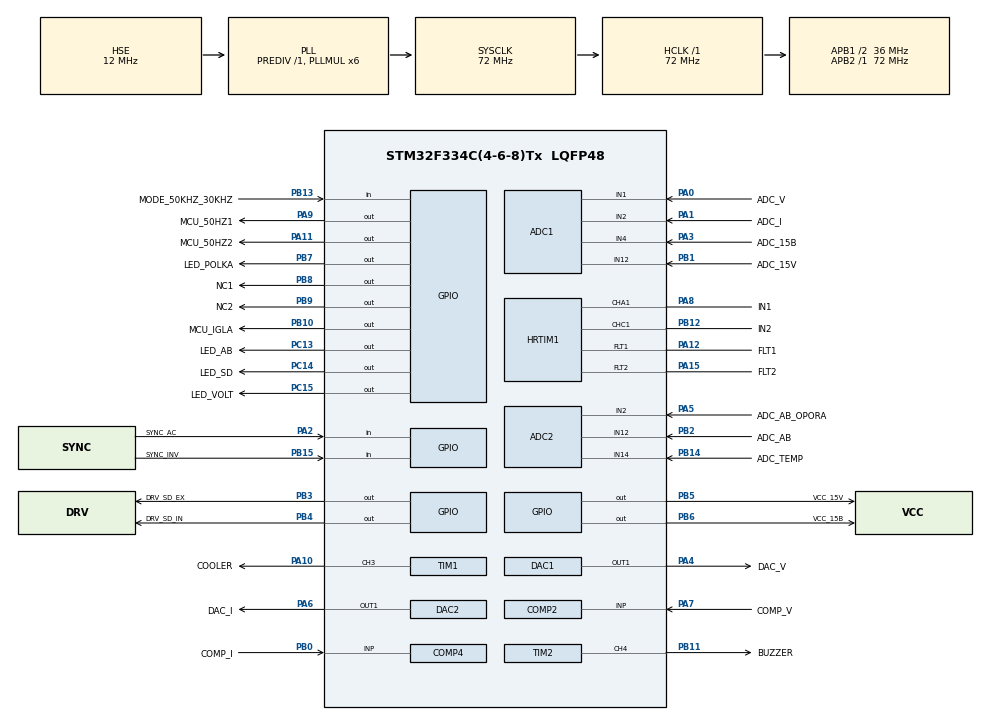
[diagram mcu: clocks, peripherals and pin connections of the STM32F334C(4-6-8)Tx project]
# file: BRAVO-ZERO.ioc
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ADC1.AWD1HighThreshold=2500
ADC1.AWD1ITMode=ENABLE
ADC1.AWD1LowThreshold=1500
ADC1.Channel-3\#ChannelRegularConversion=ADC_CHANNEL_4
ADC1.Channel-4\#ChannelRegularConversion=ADC_CHANNEL_12
ADC1.ContinuousConvMode=ENABLE
ADC1.DMAContinuousRequests=ENABLE
ADC1.EOCSelection=ADC_EOC_SEQ_CONV
ADC1.EnableAnalogWatchDog1=true
ADC1.EnableRegularConversion=ENABLE
ADC1.ExternalTrigInjecConv=ADC_EXTERNALTRIGINJECCONV_HRTIM_TRG2
ADC1.ExternalTrigInjecConvEdge=ADC_EXTERNALTRIGINJECCONV_EDGE_RISINGFALLING
ADC1.InjNumberOfConversion=2
ADC1.InjectedChannel-1\#ChannelInjectedConversion=ADC_CHANNEL_1
ADC1.InjectedChannel-2\#ChannelInjectedConversion=ADC_CHANNEL_2
ADC1.InjectedConvMode=None
ADC1.InjectedOffset-1\#ChannelInjectedConversion=0
ADC1.InjectedOffset-2\#ChannelInjectedConversion=0
ADC1.InjectedOffsetNumber-1\#ChannelInjectedConversion=ADC_OFFSET_NONE
ADC1.InjectedOffsetNumber-2\#ChannelInjectedConversion=ADC_OFFSET_NONE
ADC1.InjectedRank-1\#ChannelInjectedConversion=1
ADC1.InjectedRank-2\#ChannelInjectedConversion=2
ADC1.InjectedSamplingTime-1\#ChannelInjectedConversion=ADC_SAMPLETIME_19CYCLES_5
ADC1.InjectedSamplingTime-2\#ChannelInjectedConversion=ADC_SAMPLETIME_19CYCLES_5
ADC1.NbrOfConversion=2
ADC1.NbrOfConversionFlag=1
ADC1.Offset-3\#ChannelRegularConversion=0
ADC1.Offset-4\#ChannelRegularConversion=0
ADC1.OffsetNumber-3\#ChannelRegularConversion=ADC_OFFSET_NONE
ADC1.OffsetNumber-4\#ChannelRegularConversion=ADC_OFFSET_NONE
ADC1.QueueInjectedContext=ENABLE
ADC1.Rank-3\#ChannelRegularConversion=1
ADC1.Rank-4\#ChannelRegularConversion=2
ADC1.SamplingTime-3\#ChannelRegularConversion=ADC_SAMPLETIME_601CYCLES_5
ADC1.SamplingTime-4\#ChannelRegularConversion=ADC_SAMPLETIME_601CYCLES_5
ADC1.WatchdogMode=ADC_ANALOGWATCHDOG_ALL_REG
ADC1.master=1
ADC2.AWD1HighThreshold=2500
ADC2.AWD1ITMode=ENABLE
ADC2.AWD1LowThreshold=1500
ADC2.Channel-0\#ChannelRegularConversion=ADC_CHANNEL_14
ADC2.Channel-1\#ChannelRegularConversion=ADC_CHANNEL_12
ADC2.Channel-2\#ChannelRegularConversion=ADC_CHANNEL_2
ADC2.ContinuousConvMode=ENABLE
ADC2.DMAContinuousRequests=ENABLE
ADC2.EOCSelection=ADC_EOC_SEQ_CONV
ADC2.EnableAnalogWatchDog1=true
ADC2.EnableInjectedConversion=DISABLE
ADC2.NbrOfConversion=3
ADC2.NbrOfConversionFlag=1
ADC2.Offset-0\#ChannelRegularConversion=0
ADC2.Offset-1\#ChannelRegularConversion=0
ADC2.Offset-2\#ChannelRegularConversion=0
ADC2.OffsetNumber-0\#ChannelRegularConversion=ADC_OFFSET_NONE
ADC2.OffsetNumber-1\#ChannelRegularConversion=ADC_OFFSET_NONE
ADC2.OffsetNumber-2\#ChannelRegularConversion=ADC_OFFSET_NONE
ADC2.Rank-0\#ChannelRegularConversion=1
ADC2.Rank-1\#ChannelRegularConversion=2
ADC2.Rank-2\#ChannelRegularConversion=3
ADC2.SamplingTime-0\#ChannelRegularConversion=ADC_SAMPLETIME_601CYCLES_5
ADC2.SamplingTime-1\#ChannelRegularConversion=ADC_SAMPLETIME_601CYCLES_5
ADC2.SamplingTime-2\#ChannelRegularConversion=ADC_SAMPLETIME_601CYCLES_5
ADC2.WatchdogChannel=ADC_CHANNEL_12
COMP2.InvertingInput=COMP_INVERTINGINPUT_DAC1_CH1
COMP2.TriggerMode=COMP_TRIGGERMODE_IT_RISING_FALLING
COMP4.InvertingInput=COMP_INVERTINGINPUT_DAC2_CH1
COMP4.TriggerMode=COMP_TRIGGERMODE_IT_RISING_FALLING
Dma.ADC1.2.Direction=DMA_PERIPH_TO_MEMORY
Dma.ADC1.2.Instance=DMA1_Channel1
Dma.ADC1.2.MemDataAlignment=DMA_MDATAALIGN_HALFWORD
Dma.ADC1.2.MemInc=DMA_MINC_ENABLE
Dma.ADC1.2.Mode=DMA_CIRCULAR
Dma.ADC1.2.PeriphDataAlignment=DMA_PDATAALIGN_HALFWORD
Dma.ADC1.2.PeriphInc=DMA_PINC_DISABLE
Dma.ADC1.2.Priority=DMA_PRIORITY_HIGH
Dma.ADC2.3.Direction=DMA_PERIPH_TO_MEMORY
Dma.ADC2.3.Instance=DMA1_Channel4
Dma.ADC2.3.MemDataAlignment=DMA_MDATAALIGN_HALFWORD
Dma.ADC2.3.MemInc=DMA_MINC_ENABLE
Dma.ADC2.3.Mode=DMA_CIRCULAR
Dma.ADC2.3.PeriphDataAlignment=DMA_PDATAALIGN_HALFWORD
Dma.ADC2.3.PeriphInc=DMA_PINC_DISABLE
Dma.ADC2.3.Priority=DMA_PRIORITY_MEDIUM
Dma.Request0=TIM17_CH1/UP
Dma.Request1=TIM16_CH1/UP
Dma.Request2=ADC1
Dma.Request3=ADC2
Dma.TIM16_CH1/UP.1.Direction=DMA_PERIPH_TO_MEMORY
Dma.TIM16_CH1/UP.1.Instance=DMA1_Channel6
Dma.TIM16_CH1/UP.1.MemDataAlignment=DMA_MDATAALIGN_HALFWORD
Dma.TIM16_CH1/UP.1.MemInc=DMA_MINC_ENABLE
Dma.TIM16_CH1/UP.1.Mode=DMA_CIRCULAR
Dma.TIM16_CH1/UP.1.PeriphDataAlignment=DMA_PDATAALIGN_HALFWORD
Dma.TIM16_CH1/UP.1.PeriphInc=DMA_PINC_DISABLE
Dma.TIM16_CH1/UP.1.Priority=DMA_PRIORITY_LOW
Dma.TIM17_CH1/UP.0.Direction=DMA_PERIPH_TO_MEMORY
Dma.TIM17_CH1/UP.0.Instance=DMA1_Channel7
Dma.TIM17_CH1/UP.0.MemDataAlignment=DMA_MDATAALIGN_HALFWORD
Dma.TIM17_CH1/UP.0.MemInc=DMA_MINC_ENABLE
Dma.TIM17_CH1/UP.0.Mode=DMA_CIRCULAR
Dma.TIM17_CH1/UP.0.PeriphDataAlignment=DMA_PDATAALIGN_HALFWORD
Dma.TIM17_CH1/UP.0.PeriphInc=DMA_PINC_DISABLE
Dma.TIM17_CH1/UP.0.Priority=DMA_PRIORITY_LOW
HRTIM1.ADCTrigger_Id1=__NULL
HRTIM1.ADCTrigger_Id2=__NULL
HRTIM1.CaptureUnit1-No_output_TB=HRTIM_CAPTUREUNIT_1
HRTIM1.CaptureUnit1-No_output_TD=HRTIM_CAPTUREUNIT_1
HRTIM1.CaptureUnit1-Output_TA1=__NULL
HRTIM1.CaptureUnit1-Output_TC1=__NULL
HRTIM1.CaptureUnit2-No_output_TB=HRTIM_CAPTUREUNIT_2
HRTIM1.CaptureUnit2-No_output_TD=HRTIM_CAPTUREUNIT_2
HRTIM1.CaptureUnit2-Output_TA1=__NULL
HRTIM1.CaptureUnit2-Output_TC1=__NULL
HRTIM1.CompareUnit1-MasterTimer=HRTIM_COMPAREUNIT_1
HRTIM1.CompareUnit1-No_output_TB=__NULL
HRTIM1.CompareUnit1-Output_TA1=HRTIM_COMPAREUNIT_1
HRTIM1.CompareUnit1-Output_TC1=HRTIM_COMPAREUNIT_1
HRTIM1.CompareUnit2-MasterTimer=HRTIM_COMPAREUNIT_2
HRTIM1.CompareUnit2-Output_TA1=__NULL
HRTIM1.CompareUnit2-Output_TC1=__NULL
HRTIM1.CompareUnit3-MasterTimer=HRTIM_COMPAREUNIT_3
HRTIM1.CompareUnit3-Output_TA1=__NULL
HRTIM1.CompareUnit4-MasterTimer=HRTIM_COMPAREUNIT_4
HRTIM1.CompareUnit4-Output_TA1=__NULL
HRTIM1.CompareValue1-MasterTimer=1700
HRTIM1.CompareValue1-No_output_TB=25000
HRTIM1.CompareValue1-Output_TA1=23300
HRTIM1.CompareValue1-Output_TC1=48300
HRTIM1.CompareValue2-MasterTimer=23300
HRTIM1.CompareValue3-MasterTimer=26700
HRTIM1.CompareValue4-MasterTimer=48300
HRTIM1.Event1-Output_TA1=__NULL
HRTIM1.Event_EEV1=HRTIM_EVENT_1
HRTIM1.Event_EEV2=HRTIM_EVENT_2
HRTIM1.Event_EEV3=__NULL
HRTIM1.Event_EEV4=__NULL
HRTIM1.Event_EEV5=__NULL
HRTIM1.Event_EEV6=__NULL
HRTIM1.Event_EEV7=__NULL
HRTIM1.FastMode_EEV1=HRTIM_EVENTFASTMODE_ENABLE
HRTIM1.FastMode_EEV2=HRTIM_EVENTFASTMODE_ENABLE
HRTIM1.FaultEnable_Source1-No_output_TB=HRTIM_TIMFAULTENABLE_FAULT1
HRTIM1.FaultEnable_Source1-No_output_TD=HRTIM_TIMFAULTENABLE_FAULT1
HRTIM1.FaultEnable_Source1-Output_TA1=HRTIM_TIMFAULTENABLE_FAULT1
HRTIM1.FaultEnable_Source1-Output_TC1=HRTIM_TIMFAULTENABLE_FAULT1
HRTIM1.FaultEnable_Source2-No_output_TB=HRTIM_TIMFAULTENABLE_FAULT2
HRTIM1.FaultEnable_Source2-No_output_TD=HRTIM_TIMFAULTENABLE_FAULT2
HRTIM1.FaultEnable_Source2-Output_TA1=HRTIM_TIMFAULTENABLE_FAULT2
HRTIM1.FaultEnable_Source2-Output_TC1=HRTIM_TIMFAULTENABLE_FAULT2
HRTIM1.FaultLevel1-Output_TA1=HRTIM_OUTPUTFAULTLEVEL_INACTIVE
HRTIM1.FaultLevel1-Output_TC1=HRTIM_OUTPUTFAULTLEVEL_INACTIVE
HRTIM1.Filter_FaultLine1=HRTIM_FAULTFILTER_15
HRTIM1.Filter_FaultLine2=HRTIM_FAULTFILTER_15
HRTIM1.HRTIMInterruptResquests1=HRTIM_IT_FLT1
HRTIM1.HRTIMInterruptResquests2=HRTIM_IT_FLT2
HRTIM1.HRTIMInterruptResquests3=HRTIM_IT_SYSFLT
HRTIM1.InterruptRequests1-No_output_TB=HRTIM_TIM_IT_CPT1
HRTIM1.InterruptRequests1-No_output_TD=HRTIM_TIM_IT_CPT1
HRTIM1.InterruptRequests1_Master=HRTIM_MASTER_IT_MREP
HRTIM1.InterruptRequests2-No_output_TB=HRTIM_TIM_IT_CPT2
HRTIM1.InterruptRequests2-No_output_TD=HRTIM_TIM_IT_CPT2
HRTIM1.InterruptRequests2_Master=HRTIM_MASTER_IT_MCMP1
HRTIM1.InterruptRequests3_Master=HRTIM_MASTER_IT_MCMP2
HRTIM1.InterruptRequests4_Master=HRTIM_MASTER_IT_MCMP3
HRTIM1.InterruptRequests5_Master=HRTIM_MASTER_IT_MCMP4
HRTIM1.ModeTimeBase-No_output_TB=HRTIM_MODE_SINGLESHOT_RETRIGGERABLE
HRTIM1.ModeTimeBase-No_output_TD=HRTIM_MODE_SINGLESHOT_RETRIGGERABLE
HRTIM1.ModeTimeBase-Output_TA1=HRTIM_MODE_SINGLESHOT_RETRIGGERABLE
HRTIM1.ModeTimeBase-Output_TC1=HRTIM_MODE_SINGLESHOT_RETRIGGERABLE
HRTIM1.NumberDMARequests_Master=0
HRTIM1.NumberDMARequests_TA=0
HRTIM1.NumberDMARequests_TC=0
HRTIM1.NumberFaultEnable-No_output_TB=2
HRTIM1.NumberFaultEnable-No_output_TD=2
HRTIM1.NumberFaultEnable-Output_TA1=2
HRTIM1.NumberFaultEnable-Output_TC1=2
HRTIM1.NumberInterruptRequests-No_output_TB=2
HRTIM1.NumberInterruptRequests-No_output_TD=2
HRTIM1.NumberInterruptRequests-Output_TA1=0
HRTIM1.NumberInterruptRequests-Output_TC1=0
HRTIM1.NumberInterruptRequests_Master-MasterTimer=5
HRTIM1.NumberResetSource1-Output_TA1=7
HRTIM1.NumberResetSource1-Output_TC1=7
HRTIM1.NumberResetTrigger-No_output_TB=1
HRTIM1.NumberResetTrigger-No_output_TD=1
HRTIM1.NumberResetTrigger-Output_TA1=1
HRTIM1.NumberResetTrigger-Output_TC1=1
HRTIM1.NumberSetSource1-Output_TA1=1
HRTIM1.NumberSetSource1-Output_TC1=1
HRTIM1.NumberTriggerSource_Captureconfig1-No_output_TB=1
HRTIM1.NumberTriggerSource_Captureconfig1-No_output_TD=1
HRTIM1.NumberTriggerSource_Captureconfig2-No_output_TB=1
HRTIM1.NumberTriggerSource_Captureconfig2-No_output_TD=1
HRTIM1.NumberUpdateTrigger-No_output_TB=1
HRTIM1.NumberUpdateTrigger-No_output_TD=1
HRTIM1.NumberUpdateTrigger-Output_TA1=1
HRTIM1.NumberUpdateTrigger-Output_TC1=1
HRTIM1.Periode_MASTER=50000
HRTIM1.Periode_TA=50000
HRTIM1.Periode_TB=50000
HRTIM1.Periode_TC=50000
HRTIM1.Periode_TD=50000
HRTIM1.PreloadEnable-MasterTimer=HRTIM_PRELOAD_ENABLED
HRTIM1.PreloadEnable-No_output_TB=HRTIM_PRELOAD_ENABLED
HRTIM1.PreloadEnable-No_output_TD=HRTIM_PRELOAD_ENABLED
HRTIM1.PreloadEnable-Output_TA1=HRTIM_PRELOAD_ENABLED
HRTIM1.PreloadEnable-Output_TC1=HRTIM_PRELOAD_ENABLED
HRTIM1.PrescalerRatio_MASTER=HRTIM_PRESCALERRATIO_MUL16
HRTIM1.PrescalerRatio_TA=HRTIM_PRESCALERRATIO_MUL16
HRTIM1.PrescalerRatio_TB=HRTIM_PRESCALERRATIO_MUL16
HRTIM1.PrescalerRatio_TC=HRTIM_PRESCALERRATIO_MUL16
HRTIM1.PrescalerRatio_TD=HRTIM_PRESCALERRATIO_MUL16
HRTIM1.RepetitionUpdate-MasterTimer=HRTIM_UPDATEONREPETITION_ENABLED
HRTIM1.RepetitionUpdate-No_output_TB=HRTIM_UPDATEONREPETITION_DISABLED
HRTIM1.RepetitionUpdate-Output_TA1=HRTIM_UPDATEONREPETITION_DISABLED
HRTIM1.ResetOutput1_Source1-Output_TA1=HRTIM_OUTPUTRESET_EEV_1
HRTIM1.ResetOutput1_Source1-Output_TC1=HRTIM_OUTPUTRESET_EEV_1
HRTIM1.ResetOutput1_Source2-Output_TA1=HRTIM_OUTPUTRESET_EEV_2
HRTIM1.ResetOutput1_Source2-Output_TC1=HRTIM_OUTPUTRESET_EEV_2
HRTIM1.ResetOutput1_Source3-Output_TA1=HRTIM_OUTPUTRESET_MASTERCMP2
HRTIM1.ResetOutput1_Source3-Output_TC1=HRTIM_OUTPUTRESET_MASTERCMP4
HRTIM1.ResetOutput1_Source4-Output_TA1=HRTIM_OUTPUTRESET_MASTERCMP3
HRTIM1.ResetOutput1_Source4-Output_TC1=HRTIM_OUTPUTRESET_MASTERCMP1
HRTIM1.ResetOutput1_Source5-Output_TA1=HRTIM_OUTPUTRESET_MASTERCMP4
HRTIM1.ResetOutput1_Source5-Output_TC1=HRTIM_OUTPUTRESET_MASTERCMP2
HRTIM1.ResetOutput1_Source6-Output_TA1=HRTIM_OUTPUTRESET_MASTERPER
HRTIM1.ResetOutput1_Source6-Output_TC1=HRTIM_OUTPUTRESET_MASTERPER
HRTIM1.ResetOutput1_Source7-Output_TA1=HRTIM_OUTPUTRESET_TIMCMP1
HRTIM1.ResetOutput1_Source7-Output_TC1=HRTIM_OUTPUTRESET_TIMCMP1
HRTIM1.ResetTrigger1-No_output_TB=HRTIM_TIMRESETTRIGGER_UPDATE
HRTIM1.ResetTrigger1-No_output_TD=HRTIM_TIMRESETTRIGGER_UPDATE
HRTIM1.ResetTrigger1-Output_TA1=HRTIM_TIMRESETTRIGGER_MASTER_PER
HRTIM1.ResetTrigger1-Output_TC1=HRTIM_TIMRESETTRIGGER_MASTER_PER
HRTIM1.SetOutput1_Source1-Output_TA1=HRTIM_OUTPUTSET_MASTERCMP1
HRTIM1.SetOutput1_Source1-Output_TC1=HRTIM_OUTPUTSET_MASTERCMP3
HRTIM1.Source_EEV1=HRTIM_EVENTSRC_2
HRTIM1.TriggerCapture1_Source1-No_output_TB=HRTIM_CAPTURETRIGGER_TA1_RESET
HRTIM1.TriggerCapture1_Source1-No_output_TD=HRTIM_CAPTURETRIGGER_EEV_1
HRTIM1.TriggerCapture2_Source1-No_output_TB=HRTIM_CAPTURETRIGGER_TC1_RESET
HRTIM1.TriggerCapture2_Source1-No_output_TD=HRTIM_CAPTURETRIGGER_EEV_2
HRTIM1.UpdateTrigger1-No_output_TB=HRTIM_TIMUPDATETRIGGER_MASTER
HRTIM1.UpdateTrigger1-No_output_TD=HRTIM_TIMUPDATETRIGGER_MASTER
HRTIM1.UpdateTrigger1-Output_TA1=HRTIM_TIMUPDATETRIGGER_MASTER
HRTIM1.UpdateTrigger1-Output_TC1=HRTIM_TIMUPDATETRIGGER_MASTER
IWDG.Prescaler=IWDG_PRESCALER_256
Mcu.Family=STM32F3
Mcu.Name=STM32F334C(4-6-8)Tx
Mcu.Package=LQFP48
NVIC.COMP2_IRQn=true\:0\:0\:false\:false\:true\:false\:true
NVIC.COMP4_6_IRQn=true\:0\:0\:false\:false\:true\:false\:true
NVIC.DMA1_Channel1_IRQn=true\:0\:0\:false\:false\:true\:false\:true
NVIC.DMA1_Channel4_IRQn=true\:0\:0\:false\:false\:true\:false\:true
NVIC.DMA1_Channel6_IRQn=true\:0\:0\:false\:false\:true\:false\:true
NVIC.DMA1_Channel7_IRQn=true\:0\:0\:false\:false\:true\:false\:true
NVIC.HRTIM1_FLT_IRQn=true\:0\:0\:false\:false\:true\:true\:true
NVIC.HRTIM1_Master_IRQn=true\:0\:0\:false\:false\:true\:true\:true
NVIC.HRTIM1_TIMA_IRQn=true\:0\:0\:false\:false\:true\:true\:true
NVIC.HRTIM1_TIMB_IRQn=true\:0\:0\:false\:false\:true\:true\:true
NVIC.HRTIM1_TIMC_IRQn=true\:0\:0\:false\:false\:true\:true\:true
NVIC.HRTIM1_TIMD_IRQn=true\:0\:0\:false\:false\:true\:true\:true
NVIC.PVD_IRQn=true\:0\:0\:false\:false\:true\:true\:true
NVIC.PriorityGroup=NVIC_PRIORITYGROUP_4
PA0.GPIO_Label=ADC_V
PA0.Mode=IN1-Single-Ended
PA0.Signal=ADC1_IN1
PA1.GPIO_Label=ADC_I
PA1.Mode=IN2-Single-Ended
PA1.Signal=ADC1_IN2
PA10.GPIO_Label=COOLER
PA10.GPIO_Speed=GPIO_SPEED_FREQ_HIGH
PA10.Signal=S_TIM1_CH3
PA11.GPIO_Label=MCU_50HZ2
PA11.GPIO_Speed=GPIO_SPEED_FREQ_HIGH
PA11.Signal=GPIO_Output
PA12.GPIO_Label=FLT1
PA12.GPIO_Speed=GPIO_SPEED_FREQ_HIGH
PA12.Mode=Fault_Enable1
PA12.Signal=HRTIM1_FLT1
PA13.Mode=Serial_Wire
PA13.Signal=SYS_JTMS-SWDIO
PA14.Mode=Serial_Wire
PA14.Signal=SYS_JTCK-SWCLK
PA15.GPIO_Label=FLT2
PA15.GPIO_Speed=GPIO_SPEED_FREQ_HIGH
PA15.Mode=Fault_Enable2
PA15.Signal=HRTIM1_FLT2
PA2.GPIO_Label=SYNC_AC
PA2.Signal=GPIO_Input
PA3.GPIO_Label=ADC_15B
PA3.Mode=IN4-Single-Ended
PA3.Signal=ADC1_IN4
PA4.GPIO_Label=DAC_V
PA4.Signal=COMP_DAC11_group
PA5.GPIO_Label=ADC_AB_OPORA
PA5.Mode=IN2-Single-Ended
PA5.Signal=ADC2_IN2
PA6.GPIO_Label=DAC_I
PA6.Signal=COMP_DAC21_group
PA7.GPIO_Label=COMP_V
PA7.Mode=INP
PA7.Signal=COMP2_INP
PA8.GPIO_Label=IN1
PA8.Mode=Output_TA1
PA8.Signal=HRTIM1_CHA1
PA9.GPIO_Label=MCU_50HZ1
PA9.GPIO_Speed=GPIO_SPEED_FREQ_HIGH
PA9.Signal=GPIO_Output
PB0.GPIO_Label=COMP_I
PB0.Mode=INP
PB0.Signal=COMP4_INP
PB1.GPIO_Label=ADC_15V
PB1.Mode=IN12-Single-Ended
PB1.Signal=ADC1_IN12
PB10.GPIO_Label=MCU_IGLA
PB10.GPIO_Speed=GPIO_SPEED_FREQ_HIGH
PB10.Signal=GPIO_Output
PB11.GPIO_Label=BUZZER
PB11.GPIO_Speed=GPIO_SPEED_FREQ_HIGH
PB11.Signal=S_TIM2_CH4
PB12.GPIO_Label=IN2
PB12.Mode=Output_TC1
PB12.Signal=HRTIM1_CHC1
PB13.GPIO_Label=MODE_50KHZ_30KHZ
PB13.Signal=GPIO_Input
PB14.GPIO_Label=ADC_TEMP
PB14.Mode=IN14-Single-Ended
PB14.Signal=ADC2_IN14
PB15.GPIO_Label=SYNC_INV
PB15.Signal=GPIO_Input
PB2.GPIO_Label=ADC_AB
PB2.Mode=IN12-Single-Ended
PB2.Signal=ADC2_IN12
PB3.GPIO_Label=DRV_SD_EX
PB3.GPIO_Speed=GPIO_SPEED_FREQ_HIGH
PB3.Signal=GPIO_Output
PB4.GPIO_Label=DRV_SD_IN
PB4.GPIO_Speed=GPIO_SPEED_FREQ_HIGH
PB4.PinState=GPIO_PIN_SET
PB4.Signal=GPIO_Output
PB5.GPIO_Label=VCC_15V
PB5.GPIO_Speed=GPIO_SPEED_FREQ_HIGH
PB5.Signal=GPIO_Output
PB6.GPIO_FM6=SYSCFG_CFGR1_I2C_PB6_FMP
PB6.GPIO_Label=VCC_15B
PB6.GPIO_Speed=GPIO_SPEED_FREQ_HIGH
PB6.Signal=GPIO_Output
PB7.GPIO_FM7=SYSCFG_CFGR1_I2C_PB7_FMP
PB7.GPIO_Label=LED_POLKA
PB7.GPIO_Speed=GPIO_SPEED_FREQ_HIGH
PB7.PinState=GPIO_PIN_SET
PB7.Signal=GPIO_Output
PB8.GPIO_Label=NC1
PB8.Signal=GPIO_Output
PB9.GPIO_Label=NC2
PB9.Signal=GPIO_Output
PC13.GPIO_Label=LED_AB
PC13.GPIO_Speed=GPIO_SPEED_FREQ_LOW
PC13.PinState=GPIO_PIN_SET
PC13.Signal=GPIO_Output
PC14\ /\ OSC32_IN.GPIO_Label=LED_SD
PC14\ /\ OSC32_IN.GPIO_Speed=GPIO_SPEED_FREQ_HIGH
PC14\ /\ OSC32_IN.PinState=GPIO_PIN_SET
PC14\ /\ OSC32_IN.Signal=GPIO_Output
PC15\ /\ OSC32_OUT.GPIO_Label=LED_VOLT
PC15\ /\ OSC32_OUT.GPIO_Speed=GPIO_SPEED_FREQ_HIGH
PC15\ /\ OSC32_OUT.PinState=GPIO_PIN_SET
PC15\ /\ OSC32_OUT.Signal=GPIO_Output
PF0\ /\ OSC_IN.Mode=HSE-External-Oscillator
PF0\ /\ OSC_IN.Signal=RCC_OSC_IN
PF1\ /\ OSC_OUT.Mode=HSE-External-Oscillator
PF1\ /\ OSC_OUT.Signal=RCC_OSC_OUT
ProjectManager.HeapSize=0x200
ProjectManager.StackSize=0x400
ProjectManager.TargetToolchain=STM32CubeIDE
RCC.AHBFreq_Value=72000000
RCC.APB1CLKDivider=RCC_HCLK_DIV2
RCC.APB1Freq_Value=36000000
RCC.APB1TimFreq_Value=72000000
RCC.APB2Freq_Value=72000000
RCC.APB2TimFreq_Value=72000000
RCC.CortexFreq_Value=72000000
RCC.HCLKFreq_Value=72000000
RCC.HRTIMSelection=RCC_HRTIM1CLK_PLLCLK
RCC.HSE_VALUE=12000000
RCC.HSI_VALUE=8000000
RCC.LSE_VALUE=32768
RCC.PLLMUL=RCC_PLL_MUL6
RCC.PLLSourceVirtual=RCC_PLLSOURCE_HSE
RCC.SYSCLKFreq_VALUE=72000000
RCC.SYSCLKSourceVirtual=RCC_SYSCLKSOURCE_PLLCLK
SH.COMP_DAC11_group.0=DAC1_OUT1,DAC_OUT1
SH.COMP_DAC21_group.0=DAC2_OUT1,Switch_Enable_OUT1
SH.S_TIM1_CH3.0=TIM1_CH3,PWM Generation3 CH3
SH.S_TIM2_CH4.0=TIM2_CH4,PWM Generation4 CH4
TIM1.AutoReloadPreload=TIM_AUTORELOAD_PRELOAD_ENABLE
TIM1.Channel-PWM\ Generation3\ CH3=TIM_CHANNEL_3
TIM1.Period=35999
TIM1.Prescaler=1
TIM16.AutoReloadPreload=TIM_AUTORELOAD_PRELOAD_ENABLE
TIM16.ClockDivision=TIM_CLOCKDIVISION_DIV4
TIM16.Period=63999
TIM16.Prescaler=33749
TIM16.RepetitionCounter=0
TIM17.AutoReloadPreload=TIM_AUTORELOAD_PRELOAD_ENABLE
TIM17.ClockDivision=TIM_CLOCKDIVISION_DIV4
TIM17.Period=63999
TIM17.Prescaler=1124
TIM2.AutoReloadPreload=TIM_AUTORELOAD_PRELOAD_ENABLE
TIM2.Channel-PWM\ Generation4\ CH4=TIM_CHANNEL_4
TIM2.ClockDivision=TIM_CLOCKDIVISION_DIV1
TIM2.Period=63999
TIM2.Prescaler=5624
VP_COMP2_VS_DAC1OUT1.Mode=INM_DAC1OUT1
VP_COMP4_VS_DAC2OUT1.Mode=INM_DAC2OUT1
VP_HRTIM1_VS_hrtimMasterTimerNoOutput.Mode=MasterTimer
VP_HRTIM1_VS_hrtimTimerBNoOutput.Mode=No_output_TB
VP_HRTIM1_VS_hrtimTimerDNoOutput.Mode=No_output_TD
VP_IWDG_VS_IWDG.Mode=IWDG_Activate
VP_TIM16_VS_ClockSourceINT.Mode=Enable_Timer
VP_TIM17_VS_ClockSourceINT.Mode=Enable_Timer
VP_TIM1_VS_ClockSourceINT.Mode=Internal
VP_TIM2_VS_ClockSourceINT.Mode=Internal
board=custom

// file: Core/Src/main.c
/* USER CODE BEGIN Header */
/**
  ******************************************************************************
  * @file           : main.c
  * @brief          : Main program body
  ******************************************************************************
  * @attention
  *
  * <h2><center>&copy; Copyright (c) 2020 STMicroelectronics.
  * All rights reserved.</center></h2>
  *
  * This software component is licensed by ST under BSD 3-Clause license,
  * the "License"; You may not use this file except in compliance with the
  * License. You may obtain a copy of the License at:
  *                        opensource.org/licenses/BSD-3-Clause
  *
  ******************************************************************************
  */
/* USER CODE END Header */

#include "main.h"
#include "adc.h"
#include "comp.h"
#include "dac.h"
#include "dma.h"
#include "hrtim.h"
#include "iwdg.h"
#include "tim.h"
#include "gpio.h"

/* USER CODE BEGIN Includes */
#include "BRAVO_hal.h"
/* USER CODE END Includes */

void SystemClock_Config(void);

int main(void)
{
  /* USER CODE BEGIN 1 */
	Enable_SH_DEBUG();
  /* USER CODE END 1 */

  /* MCU Configuration--------------------------------------------------------*/

  /* Reset of all peripherals, Initializes the Flash interface and the Systick. */
  HAL_Init();

  /* Configure the system clock */
  SystemClock_Config();

  /* Initialize all configured peripherals */
  MX_GPIO_Init();
  MX_DMA_Init();
  MX_IWDG_Init();
  MX_ADC1_Init();
  MX_COMP2_Init();
  MX_COMP4_Init();
  MX_DAC1_Init();
  MX_DAC2_Init();
  MX_TIM1_Init();
  MX_TIM2_Init();
  MX_TIM16_Init();
  MX_TIM17_Init();
  MX_ADC2_Init();
  MX_HRTIM1_Init();
  /* USER CODE BEGIN 2 */

  BRAVO_Stop(); // STOP HRTIM
  VCC15V_ON(); // ON 15V POWER SUPPY
  COMP_DAC_Start(); // Start all DACs and COMPs

  BRAVO_SoftStart_ON(); // enable Soft Start

  BRAVO_Start(); // START HRTIM

  // Polka Settings
  //POLKA_MODE=1;
  //POLKA_LEVEL=3000;
  //POLKA_ROLLBACK=POLKA_ROLLBACK_MAX_CNT;

  /* USER CODE END 2 */

  /* Infinite loop */
  while (1)
  {

    /* USER CODE BEGIN 3 */
	HAL_IWDG_Refresh(&hiwdg); // RESET IWDG

	if (BRAVO_ON==0) {
		BRAVO_SoftStart_OFF(); // skip softstart
		BRAVO_Start(); // START HRTIM
	}
  }
  /* USER CODE END 3 */
}

void SystemClock_Config(void)
{
  RCC_OscInitTypeDef RCC_OscInitStruct = {0};
  RCC_ClkInitTypeDef RCC_ClkInitStruct = {0};
  RCC_PeriphCLKInitTypeDef PeriphClkInit = {0};

  /** Initializes the CPU, AHB and APB busses clocks
  */
  RCC_OscInitStruct.OscillatorType = RCC_OSCILLATORTYPE_LSI|RCC_OSCILLATORTYPE_HSE;
  RCC_OscInitStruct.HSEState = RCC_HSE_ON;
  RCC_OscInitStruct.HSEPredivValue = RCC_HSE_PREDIV_DIV1;
  RCC_OscInitStruct.HSIState = RCC_HSI_ON;
  RCC_OscInitStruct.LSIState = RCC_LSI_ON;
  RCC_OscInitStruct.PLL.PLLState = RCC_PLL_ON;
  RCC_OscInitStruct.PLL.PLLSource = RCC_PLLSOURCE_HSE;
  RCC_OscInitStruct.PLL.PLLMUL = RCC_PLL_MUL6;
  if (HAL_RCC_OscConfig(&RCC_OscInitStruct) != HAL_OK)
  {
    Error_Handler();
  }
  /** Initializes the CPU, AHB and APB busses clocks
  */
  RCC_ClkInitStruct.ClockType = RCC_CLOCKTYPE_HCLK|RCC_CLOCKTYPE_SYSCLK
                              |RCC_CLOCKTYPE_PCLK1|RCC_CLOCKTYPE_PCLK2;
  RCC_ClkInitStruct.SYSCLKSource = RCC_SYSCLKSOURCE_PLLCLK;
  RCC_ClkInitStruct.AHBCLKDivider = RCC_SYSCLK_DIV1;
  RCC_ClkInitStruct.APB1CLKDivider = RCC_HCLK_DIV2;
  RCC_ClkInitStruct.APB2CLKDivider = RCC_HCLK_DIV1;

  if (HAL_RCC_ClockConfig(&RCC_ClkInitStruct, FLASH_LATENCY_2) != HAL_OK)
  {
    Error_Handler();
  }
  PeriphClkInit.PeriphClockSelection = RCC_PERIPHCLK_HRTIM1|RCC_PERIPHCLK_TIM1
                              |RCC_PERIPHCLK_ADC12;
  PeriphClkInit.Adc12ClockSelection = RCC_ADC12PLLCLK_DIV1;
  PeriphClkInit.Tim1ClockSelection = RCC_TIM1CLK_HCLK;
  PeriphClkInit.Hrtim1ClockSelection = RCC_HRTIM1CLK_PLLCLK;
  if (HAL_RCCEx_PeriphCLKConfig(&PeriphClkInit) != HAL_OK)
  {
    Error_Handler();
  }
}

void Error_Handler(void)
{
}

/************************ (C) COPYRIGHT STMicroelectronics *****END OF FILE****/
